# SIBG301M104LGH register map
Vendor: Silicon Labs; Series: Si; File version: B
Registers are 32-bit, read-write, reset 0x0 unless marked. A register's access mark holds for its fields unless they carry their own. Offsets are from the block's base; [hi:lo] are bit positions; {n}, {i} and the like mark numbered series; 'fields as' and 'values as' point back to an identical list.

## SYSCFG_NS — SYSCFG_NS Registers
Base 0x40874000
Same registers: SYSCFG_S 0x50874000
0x04 IPVERSION ro reset 0xA
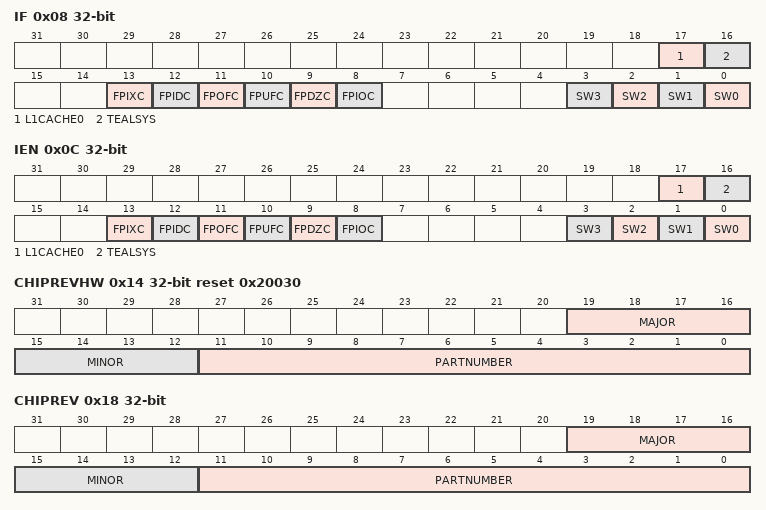
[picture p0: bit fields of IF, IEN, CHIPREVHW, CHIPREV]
0x08 IF — Read to get system status.
  [17] L1CACHE0 — L1CACHE bus error
  [16] TEALSYS — TEALSYS bus error
  [13] FPIXC — FPU Inexact interrupt flag
  [12] FPIDC — FPU Input denormal interrupt flag
  [11] FPOFC — FPU Overflow interrupt flag
  [10] FPUFC — FPU Underflow interrupt flag
  [9] FPDZC — FPU Divide by zero interrupt flag
  [8] FPIOC — FPU Invalid Operation interrupt flag
  [n] SW{n} (n=0..3) — Software Interrupt Flag
0x0C IEN — Write to enable interrupts.
  [17] L1CACHE0 — L1CACHE bus error enable
  [16] TEALSYS — TEALSYS bus error enable
  [13] FPIXC — FPU Inexact Interrupt Enable
  [12] FPIDC — FPU Input denormal Interrupt Enable
  [11] FPOFC — FPU Overflow Interrupt Enable
  [10] FPUFC — FPU Underflow Interrupt Enable
  [9] FPDZC — FPU Divide by zero Interrupt Enable
  [8] FPIOC — FPU Invalid Operation Interrupt Enable
  [n] SW{n} (n=0..3) — Software Interrupt Enable
0x14 CHIPREVHW reset 0x20030 — Read to get the hard-wired chip revision.
  [19:16] MAJOR ro — Hardwired Chip Major value
  [15:12] MINOR ro — Hardwired Chip Minor value
  [11:0] PARTNUMBER — Chip Part Number value
0x18 CHIPREV — Read to get the chip revision programmed by feature configuration.
  [19:16] MAJOR — Chip Revision Major value
  [15:12] MINOR — Chip Revision Minor value
  [11:0] PARTNUMBER — Chip Part Number value
0x24 CFGSYSTIC — Configure the source of the system tick for the M33.
  [0] SYSTICEXTCLKEN — SysTick External Clock Enable
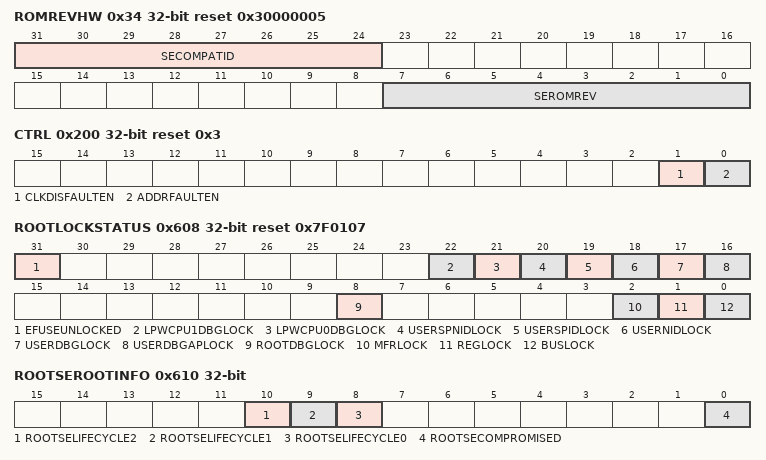
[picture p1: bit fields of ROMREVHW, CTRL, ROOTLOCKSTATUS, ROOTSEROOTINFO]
0x34 ROMREVHW ro reset 0x30000005 — Read to get the hard-wired ROM revision.
  [31:24] SECOMPATID, [7:0] SEROMREV
0x200 CTRL reset 0x3 — Configure to provide general RAM configuration.
  [1] CLKDISFAULTEN — Disabled Clkbus Bus Fault Enable
  [0] ADDRFAULTEN — Invalid Address Bus Fault Response Enabl
0x600 ROOTDATA0 — Generic data space for user to pass to root, e.g., address of struct in mem
  [31:0] DATA
0x604 ROOTDATA1 — Generic data space for user to pass to root, e.g., address of struct in mem
  [31:0] DATA
0x608 ROOTLOCKSTATUS ro reset 0x7F0107 — This register returns the status of the SE managed locks.
  [31] EFUSEUNLOCKED
  [22] LPWCPU1DBGLOCK — LPW CPU1 Debug Lock
  [21] LPWCPU0DBGLOCK — LPW CPU0 Debug Lock
  [20] USERSPNIDLOCK — User Secure Non-invasive Debug Lock
  [19] USERSPIDLOCK — User Secure Invasive Debug Lock
  [18] USERNIDLOCK — User Non-invasive Debug Lock
  [17] USERDBGLOCK — User Invasive Debug Lock
  [16] USERDBGAPLOCK — User Debug Access Port Lock
  [8] ROOTDBGLOCK — Root Debug Lock
  [2] MFRLOCK — Manufacture Lock
  [1] REGLOCK — Register Lock
  [0] BUSLOCK
0x60C ROOTSESWVERSION — SE Software version
  [31:0] SWVERSION
0x610 ROOTSEROOTINFO — SE Root Information
  [10] ROOTSELIFECYCLE2, [9] ROOTSELIFECYCLE1, [8] ROOTSELIFECYCLE0, [0] ROOTSECOMPROMISED
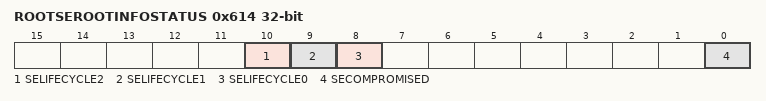
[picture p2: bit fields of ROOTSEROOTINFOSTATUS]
0x614 ROOTSEROOTINFOSTATUS ro — SE Root Information Status
  [10] SELIFECYCLE2, [9] SELIFECYCLE1, [8] SELIFECYCLE0, [0] SECOMPROMISED

## SYSCFG_NS_CFGNS — SYSCFG_NS_CFGNS Registers
Base 0x40870000
Same registers: SYSCFG_S_CFGNS 0x50870000
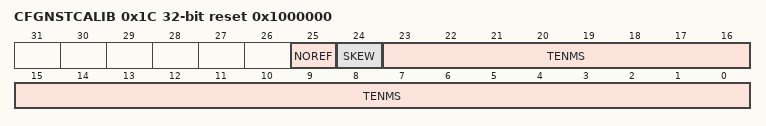
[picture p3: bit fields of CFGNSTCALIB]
0x1C CFGNSTCALIB reset 0x1000000 — Configure to define the system tick for the M33.
  [25] NOREF — No Reference
    0=REF (Reference clock is implemented); 1=NOREF (Reference clock is not implemented)
  [24] SKEW
  [23:0] TENMS — Ten Milliseconds
0x600 ROOTNSDATA0 — Generic data space for user to pass to root, e.g., address of struct in mem
  [31:0] DATA
0x604 ROOTNSDATA1 — Generic data space for user to pass to root, e.g., address of struct in mem
  [31:0] DATA

## SYSRTC0_NS — SYSRTC0_NS Registers
Base 0xA3000000
Same registers: SYSRTC0_S 0xB3000000
0x00 IPVERSION ro reset 0x2
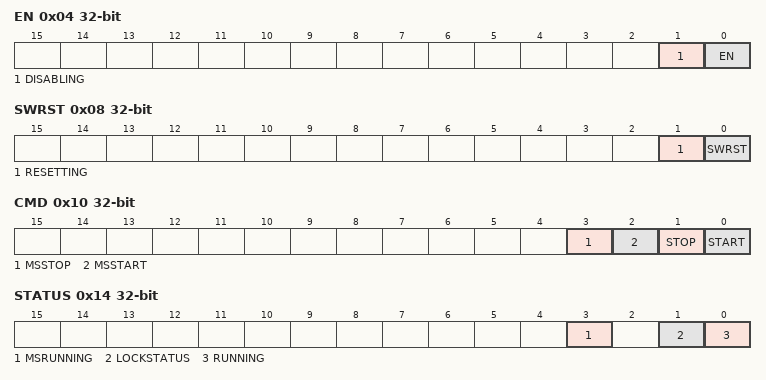
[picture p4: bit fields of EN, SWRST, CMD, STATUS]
0x04 EN
  [1] DISABLING ro — Disablement busy status
  [0] EN — SYSRTC Enable
0x08 SWRST
  [1] RESETTING ro — Software reset busy status
  [0] SWRST wo — Software reset command
0x0C CFG
  [0] DEBUGRUN — Debug Mode Run Enable
    0=DISABLE (SYSRTC is frozen in debug mode); 1=ENABLE (SYSRTC is running in debug mode)
0x10 CMD wo
  [3] MSSTOP — stop ms counter
  [2] MSSTART — Start ms counter
  [1] STOP — Stop SYSRTC
  [0] START — Start SYSRTC
0x14 STATUS ro
  [3] MSRUNNING — MS-Counter running status
  [1] LOCKSTATUS
    0=UNLOCKED (SYSRTC registers are unlocked); 1=LOCKED (SYSRTC registers are locked)
  [0] RUNNING — SYSRTC running status
0x18 CNT
  [31:0] CNT — Counter Value
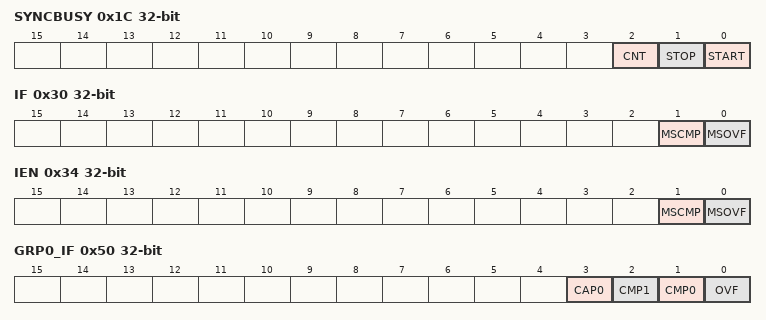
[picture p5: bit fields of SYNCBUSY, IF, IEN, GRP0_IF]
0x1C SYNCBUSY ro
  [2] CNT — Sync busy for CNT bitfield
  [1] STOP — Sync busy for STOP bitfield
  [0] START — Sync busy for START bitfield
0x20 LOCK wo
  [15:0] LOCKKEY — Configuration Lock Key
    0x4776=UNLOCK (Write to unlock SYSRTC lockable registers)
0x24 MSCNT ro
  [31:0] MSCNT — MS-Counter
0x28 MSCMPVAL
  [31:0] MSCMPVAL — Compare val for MSCounter
0x2C MSCMPBUF
  [31:0] MSCMPBUF — Buffered Compare for MSCounter
0x30 IF
  [1] MSCMP — MS Counter Compare
  [0] MSOVF — MS Counter Overflow
0x34 IEN
  [1] MSCMP — MS Counter Compare
  [0] MSOVF — MS Counter Overflow
0x50 GRP0_IF
  [3] CAP0 — Capture 0 Interrupt Flag
  [2] CMP1 — Compare 1 Interrupt Flag
  [1] CMP0 — Compare 0 Interrupt Flag
  [0] OVF — Overflow Interrupt Flag
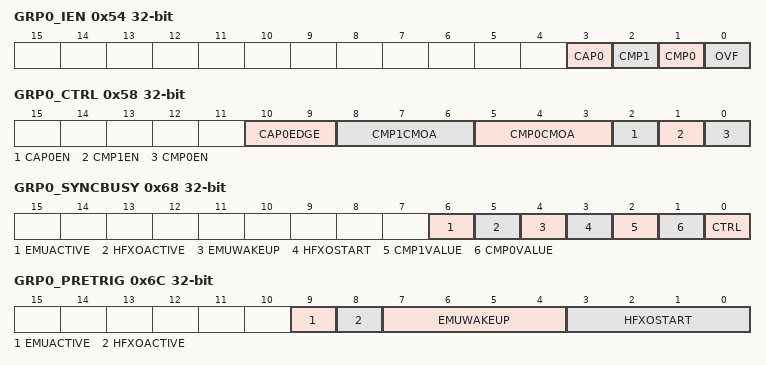
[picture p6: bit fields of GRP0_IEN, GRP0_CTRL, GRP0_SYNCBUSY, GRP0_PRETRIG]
0x54 GRP0_IEN
  [3] CAP0 — Capture 0 Interrupt Enable
  [2] CMP1 — Compare 1 Interrupt Enable
  [1] CMP0 — Compare 0 Interrupt Enable
  [0] OVF — Overflow Interrupt Enable
0x58 GRP0_CTRL
  [10:9] CAP0EDGE — Capture 0 Edge Select
    0=RISING (Rising edges detected); 1=FALLING (Falling edges detected); 2=BOTH (Both edges detected)
  [8:6] CMP1CMOA — Compare 1 Compare Match Output Action
    0=CLEAR (Cleared on the next cycle); 1=SET (Set on the next cycle); 2=PULSE (Set on the next cycle, cleared on the cycle after); 3=TOGGLE (Inverted on the next cycle); 4=CMPIF (Export this channel's CMP IF)
  [5:3] CMP0CMOA — Compare 0 Compare Match Output Action
    values as CMP1CMOA
  [2] CAP0EN — Capture 0 Enable
  [1] CMP1EN — Compare 1 Enable
  [0] CMP0EN — Compare 0 Enable
0x5C GRP0_CMP0VALUE
  [31:0] CMP0VALUE — Compare 0 Value
0x60 GRP0_CMP1VALUE
  [31:0] CMP1VALUE — Compare 1 Value
0x64 GRP0_CAP0VALUE ro
  [31:0] CAP0VALUE — Capture 0 Value
0x68 GRP0_SYNCBUSY ro
  [6] EMUACTIVE — Sync busy for EMUACTIVE bit
  [5] HFXOACTIVE — Sync busy for HFXOACTIVE bit
  [4] EMUWAKEUP — Sync busy for EMUWAKEUP bit
  [3] HFXOSTART — Sync busy for HFXOSTART bit
  [2] CMP1VALUE — Sync busy for CMP1VALUE register
  [1] CMP0VALUE — Sync busy for CMP0VALUE register
  [0] CTRL — Sync busy for CTRL register
0x6C GRP0_PRETRIG
  [9] EMUACTIVE — Status bit for EMU pretrigger
  [8] HFXOACTIVE — Status bit for HFXO pretrigger
  [7:4] EMUWAKEUP — Cfg reg for Pretrigger event
  [3:0] HFXOSTART — Cfg reg for Pretrigger event
